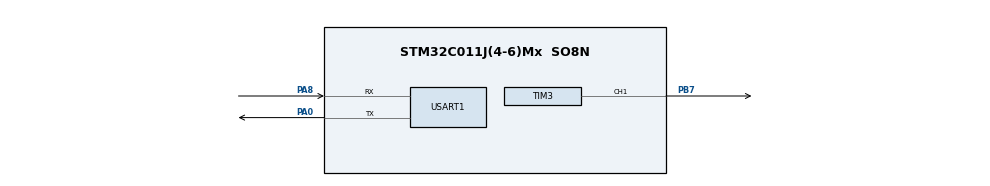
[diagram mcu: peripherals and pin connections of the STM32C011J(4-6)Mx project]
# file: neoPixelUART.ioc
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Dma.Request0=USART1_RX
Dma.Request1=TIM3_CH1
Dma.TIM3_CH1.1.Direction=DMA_MEMORY_TO_PERIPH
Dma.TIM3_CH1.1.EventEnable=DISABLE
Dma.TIM3_CH1.1.Instance=DMA1_Channel2
Dma.TIM3_CH1.1.MemDataAlignment=DMA_MDATAALIGN_HALFWORD
Dma.TIM3_CH1.1.MemInc=DMA_MINC_ENABLE
Dma.TIM3_CH1.1.Mode=DMA_NORMAL
Dma.TIM3_CH1.1.PeriphDataAlignment=DMA_PDATAALIGN_HALFWORD
Dma.TIM3_CH1.1.PeriphInc=DMA_PINC_DISABLE
Dma.TIM3_CH1.1.Polarity=HAL_DMAMUX_REQ_GEN_RISING
Dma.TIM3_CH1.1.Priority=DMA_PRIORITY_LOW
Dma.TIM3_CH1.1.RequestNumber=1
Dma.TIM3_CH1.1.SignalID=NONE
Dma.TIM3_CH1.1.SyncEnable=DISABLE
Dma.TIM3_CH1.1.SyncPolarity=HAL_DMAMUX_SYNC_NO_EVENT
Dma.TIM3_CH1.1.SyncRequestNumber=1
Dma.TIM3_CH1.1.SyncSignalID=NONE
Dma.USART1_RX.0.Direction=DMA_PERIPH_TO_MEMORY
Dma.USART1_RX.0.EventEnable=DISABLE
Dma.USART1_RX.0.Instance=DMA1_Channel1
Dma.USART1_RX.0.MemDataAlignment=DMA_MDATAALIGN_BYTE
Dma.USART1_RX.0.MemInc=DMA_MINC_ENABLE
Dma.USART1_RX.0.Mode=DMA_CIRCULAR
Dma.USART1_RX.0.PeriphDataAlignment=DMA_PDATAALIGN_BYTE
Dma.USART1_RX.0.PeriphInc=DMA_PINC_DISABLE
Dma.USART1_RX.0.Polarity=HAL_DMAMUX_REQ_GEN_RISING
Dma.USART1_RX.0.Priority=DMA_PRIORITY_LOW
Dma.USART1_RX.0.RequestNumber=1
Dma.USART1_RX.0.SignalID=NONE
Dma.USART1_RX.0.SyncEnable=DISABLE
Dma.USART1_RX.0.SyncPolarity=HAL_DMAMUX_SYNC_NO_EVENT
Dma.USART1_RX.0.SyncRequestNumber=1
Dma.USART1_RX.0.SyncSignalID=NONE
Mcu.Family=STM32C0
Mcu.Name=STM32C011J(4-6)Mx
Mcu.Package=SO8N
NVIC.DMA1_Channel1_IRQn=true\:0\:0\:false\:false\:true\:false\:true\:true
NVIC.DMA1_Channel2_3_IRQn=true\:0\:0\:false\:false\:true\:false\:true\:true
PA0.Mode=Asynchronous
PA0.Signal=USART1_TX
PA13.Mode=Serial_Wire
PA13.Signal=DEBUG_SWDIO
PA14-BOOT0.Mode=Serial_Wire
PA14-BOOT0.Signal=DEBUG_SWCLK
PA8.Mode=Asynchronous
PA8.Signal=USART1_RX
PA8__PA11\ [PA9].StandardMode=true
PB7.Signal=S_TIM3_CH1
PC14-OSCX_IN\ (PC14)__PB7.StandardMode=true
PC15-OSCX_OUT\ (PC15)__PA14-BOOT0__PB6.StandardMode=true
PF2-NRST__PA0__PA1__PA2.StandardMode=true
ProjectManager.HeapSize=0x200
ProjectManager.StackSize=0x400
ProjectManager.TargetToolchain=STM32CubeIDE
RCC.ADCFreq_Value=48000000
RCC.AHBFreq_Value=48000000
RCC.CortexFreq_Value=48000000
RCC.EXTERNAL_CLOCK_VALUE=12288000
RCC.HCLKFreq_Value=48000000
RCC.HSE_VALUE=8000000
RCC.HSISYSCLKDivider=RCC_HSI_DIV1
RCC.HSI_VALUE=48000000
RCC.LSE_VALUE=32768
RCC.SYSCLKFreq_VALUE=48000000
SH.S_TIM3_CH1.0=TIM3_CH1,PWM Generation1 CH1
TIM3.Channel-PWM\ Generation1\ CH1=TIM_CHANNEL_1
TIM3.Period=38
USART1.VirtualMode-Asynchronous=VM_ASYNC
VP_TIM3_VS_ClockSourceINT.Mode=Internal
board=custom

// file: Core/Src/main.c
/* USER CODE BEGIN Header */
/**
  ******************************************************************************
  * @file           : main.c
  * @brief          : Main program body
  ******************************************************************************
  * @attention
  *
  * Copyright (c) 2023 STMicroelectronics.
  * All rights reserved.
  *
  * This software is licensed under terms that can be found in the LICENSE file
  * in the root directory of this software component.
  * If no LICENSE file comes with this software, it is provided AS-IS.
  *
  ******************************************************************************
  */
/* USER CODE END Header */
#include "main.h"

/* USER CODE BEGIN Includes */
#include <string.h>
#include "tasks.h"
/* USER CODE END Includes */

TIM_HandleTypeDef htim3;
DMA_HandleTypeDef hdma_tim3_ch1;

UART_HandleTypeDef huart1;
DMA_HandleTypeDef hdma_usart1_rx;

void SystemClock_Config(void);
static void MX_GPIO_Init(void);
static void MX_DMA_Init(void);
static void MX_USART1_UART_Init(void);
static void MX_TIM3_Init(void);

int main(void)
{

  /* MCU Configuration--------------------------------------------------------*/

  /* Reset of all peripherals, Initializes the Flash interface and the Systick. */
  HAL_Init();

  /* Configure the system clock */
  SystemClock_Config();

  /* Initialize all configured peripherals */
  MX_GPIO_Init();
  MX_DMA_Init();
  MX_USART1_UART_Init();
  MX_TIM3_Init();
  /* USER CODE BEGIN 2 */
  tasksInit();
  /* USER CODE END 2 */

  /* Infinite loop */
  /* USER CODE BEGIN WHILE */
  while (1)
  {
    tasksSchedule();
    HAL_Delay(0); // actually 1ms
    /* USER CODE END WHILE */

  }
}

void SystemClock_Config(void)
{
  RCC_OscInitTypeDef RCC_OscInitStruct = {0};
  RCC_ClkInitTypeDef RCC_ClkInitStruct = {0};

  /** Initializes the RCC Oscillators according to the specified parameters
  * in the RCC_OscInitTypeDef structure.
  */
  RCC_OscInitStruct.OscillatorType = RCC_OSCILLATORTYPE_HSI;
  RCC_OscInitStruct.HSIState = RCC_HSI_ON;
  RCC_OscInitStruct.HSIDiv = RCC_HSI_DIV1;
  RCC_OscInitStruct.HSICalibrationValue = RCC_HSICALIBRATION_DEFAULT;
  if (HAL_RCC_OscConfig(&RCC_OscInitStruct) != HAL_OK)
  {
    Error_Handler();
  }

  /** Initializes the CPU, AHB and APB buses clocks
  */
  RCC_ClkInitStruct.ClockType = RCC_CLOCKTYPE_HCLK|RCC_CLOCKTYPE_SYSCLK
                              |RCC_CLOCKTYPE_PCLK1;
  RCC_ClkInitStruct.SYSCLKSource = RCC_SYSCLKSOURCE_HSI;
  RCC_ClkInitStruct.SYSCLKDivider = RCC_SYSCLK_DIV1;
  RCC_ClkInitStruct.AHBCLKDivider = RCC_HCLK_DIV1;
  RCC_ClkInitStruct.APB1CLKDivider = RCC_APB1_DIV1;

  if (HAL_RCC_ClockConfig(&RCC_ClkInitStruct, FLASH_LATENCY_1) != HAL_OK)
  {
    Error_Handler();
  }
}

static void MX_TIM3_Init(void)
{

  TIM_ClockConfigTypeDef sClockSourceConfig = {0};
  TIM_MasterConfigTypeDef sMasterConfig = {0};
  TIM_OC_InitTypeDef sConfigOC = {0};

  htim3.Instance = TIM3;
  htim3.Init.Prescaler = 0;
  htim3.Init.CounterMode = TIM_COUNTERMODE_UP;
  htim3.Init.Period = 38;
  htim3.Init.ClockDivision = TIM_CLOCKDIVISION_DIV1;
  htim3.Init.AutoReloadPreload = TIM_AUTORELOAD_PRELOAD_DISABLE;
  if (HAL_TIM_Base_Init(&htim3) != HAL_OK)
  {
    Error_Handler();
  }
  sClockSourceConfig.ClockSource = TIM_CLOCKSOURCE_INTERNAL;
  if (HAL_TIM_ConfigClockSource(&htim3, &sClockSourceConfig) != HAL_OK)
  {
    Error_Handler();
  }
  if (HAL_TIM_PWM_Init(&htim3) != HAL_OK)
  {
    Error_Handler();
  }
  sMasterConfig.MasterOutputTrigger = TIM_TRGO_RESET;
  sMasterConfig.MasterSlaveMode = TIM_MASTERSLAVEMODE_DISABLE;
  if (HAL_TIMEx_MasterConfigSynchronization(&htim3, &sMasterConfig) != HAL_OK)
  {
    Error_Handler();
  }
  sConfigOC.OCMode = TIM_OCMODE_PWM1;
  sConfigOC.Pulse = 0;
  sConfigOC.OCPolarity = TIM_OCPOLARITY_HIGH;
  sConfigOC.OCFastMode = TIM_OCFAST_DISABLE;
  if (HAL_TIM_PWM_ConfigChannel(&htim3, &sConfigOC, TIM_CHANNEL_1) != HAL_OK)
  {
    Error_Handler();
  }
  HAL_TIM_MspPostInit(&htim3);

}

static void MX_USART1_UART_Init(void)
{

  huart1.Instance = USART1;
  huart1.Init.BaudRate = 115200;
  huart1.Init.WordLength = UART_WORDLENGTH_8B;
  huart1.Init.StopBits = UART_STOPBITS_1;
  huart1.Init.Parity = UART_PARITY_NONE;
  huart1.Init.Mode = UART_MODE_TX_RX;
  huart1.Init.HwFlowCtl = UART_HWCONTROL_NONE;
  huart1.Init.OverSampling = UART_OVERSAMPLING_16;
  huart1.Init.OneBitSampling = UART_ONE_BIT_SAMPLE_DISABLE;
  huart1.Init.ClockPrescaler = UART_PRESCALER_DIV1;
  huart1.AdvancedInit.AdvFeatureInit = UART_ADVFEATURE_NO_INIT;
  if (HAL_UART_Init(&huart1) != HAL_OK)
  {
    Error_Handler();
  }
  if (HAL_UARTEx_SetTxFifoThreshold(&huart1, UART_TXFIFO_THRESHOLD_1_8) != HAL_OK)
  {
    Error_Handler();
  }
  if (HAL_UARTEx_SetRxFifoThreshold(&huart1, UART_RXFIFO_THRESHOLD_1_8) != HAL_OK)
  {
    Error_Handler();
  }
  if (HAL_UARTEx_DisableFifoMode(&huart1) != HAL_OK)
  {
    Error_Handler();
  }

}

static void MX_DMA_Init(void)
{

  /* DMA controller clock enable */
  __HAL_RCC_DMA1_CLK_ENABLE();

  /* DMA interrupt init */
  /* DMA1_Channel1_IRQn interrupt configuration */
  HAL_NVIC_SetPriority(DMA1_Channel1_IRQn, 0, 0);
  HAL_NVIC_EnableIRQ(DMA1_Channel1_IRQn);
  /* DMA1_Channel2_3_IRQn interrupt configuration */
  HAL_NVIC_SetPriority(DMA1_Channel2_3_IRQn, 0, 0);
  HAL_NVIC_EnableIRQ(DMA1_Channel2_3_IRQn);

}

static void MX_GPIO_Init(void)
{

  /* GPIO Ports Clock Enable */
  __HAL_RCC_GPIOB_CLK_ENABLE();
  __HAL_RCC_GPIOA_CLK_ENABLE();

}

void Error_Handler(void)
{
  __disable_irq();
  while (1)
  {
  }
}
